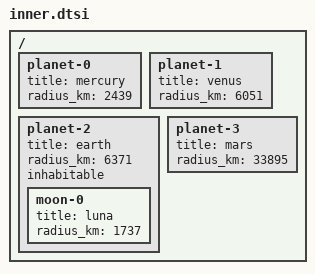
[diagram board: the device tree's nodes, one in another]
/ {
	planet-0 {
		title = "mercury";
		radius_km = <2439>;
	};

	planet-1 {
		title = "venus";
		radius_km = <6051>;
	};

	planet-2 {
		title = "earth";
		radius_km = <6371>;
		inhabitable;

		moon-0 {
			title = "luna";
			radius_km = <1737>;
		};

	};

	planet-3 {
		title = "mars";
		radius_km = <33895>;
	};
};
